# GD32F5xx register map
File version: 1.0
CPU: CM33 r0p1, little endian, MPU, FPU, 4 interrupt priority bits
Registers are 32-bit, read-write, reset 0x0 unless marked. A register's access mark holds for its fields unless they carry their own. Offsets are from the block's base; [hi:lo] are bit positions.

## TIMER9 — General-purpose-timers
Base 0x40014400
Same registers: TIMER12 0x40001C00, TIMER13 0x40002000
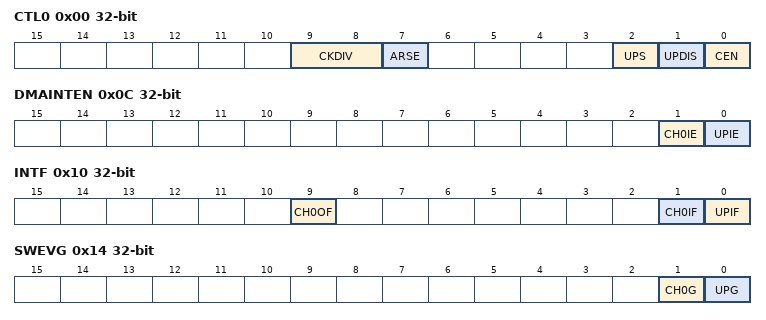
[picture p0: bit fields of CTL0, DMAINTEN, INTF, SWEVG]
0x00 CTL0 — control register 0
  [9:8] CKDIV — Clock division
  [7] ARSE — Auto-reload shadow enable
  [2] UPS — Update source
  [1] UPDIS — Update disable
  [0] CEN — Counter enable
0x04 CTL1 — control register 1
  [6:4] MMC — Master mode control
0x0C DMAINTEN — DMA/Interrupt enable register
  [1] CH0IE — Channel 0 capture/compare interrupt enable
  [0] UPIE — Update interrupt enable
0x10 INTF — interrupt flag register
  [9] CH0OF — Channel 0 over capture flag
  [1] CH0IF — Channel 0 capture/compare interrupt flag
  [0] UPIF — Update interrupt flag
0x14 SWEVG wo — event generation register
  [1] CH0G — Channel 0 capture or compare event generation
  [0] UPG — Update generation
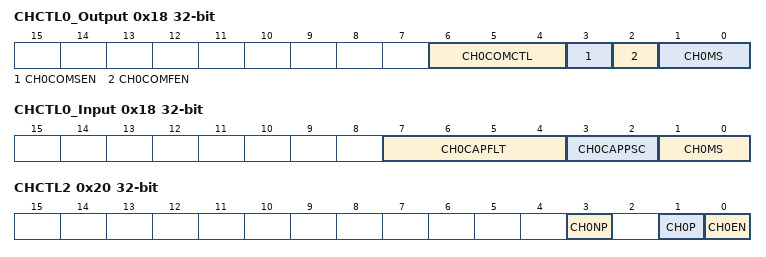
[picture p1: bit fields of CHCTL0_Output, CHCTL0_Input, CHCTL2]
0x18 CHCTL0_Output — Channel control register 0 (output mode)
  [6:4] CH0COMCTL — Channel 0 compare output control
  [3] CH0COMSEN — Channel 0 compare output shadow enable
  [2] CH0COMFEN — Channel 0 output compare fast enable
  [1:0] CH0MS — Channel 0 I/O mode selection
0x18 CHCTL0_Input (alternate view of CHCTL0_Output) — Channel control register 0 ( (input mode)
  [7:4] CH0CAPFLT — Channel 0 input capture filter control
  [3:2] CH0CAPPSC — Channel 0 input capture prescaler
  [1:0] CH0MS — Channel 0 mode selection
0x20 CHCTL2 — Channel control register 2
  [3] CH0NP — Channel 0 complementary output polarity
  [1] CH0P — Channel 0 capture/compare polarity
  [0] CH0EN — Channel 0 capture/compare function enable
0x24 CNT — Counter register
  [15:0] CNT — current counter value
0x28 PSC — Prescaler register
  [15:0] PSC — Prescaler value of the counter clock
0x2C CAR — Counter auto reload register
  [15:0] CARL — Counter auto reload value
0x34 CH0CV — Channel 0 capture/compare value register
  [15:0] CH0VAL — Capture or compare value of channel 0
0x50 IRMP — channel input remap register
  [11:10] ITI1_RMP — Internal trigger input1 remap
0xFC CFG — configuration register
  [1] CHVSEL — Write CHxVAL register selection

## TIMER10 — General level2 timer
Base 0x40014800
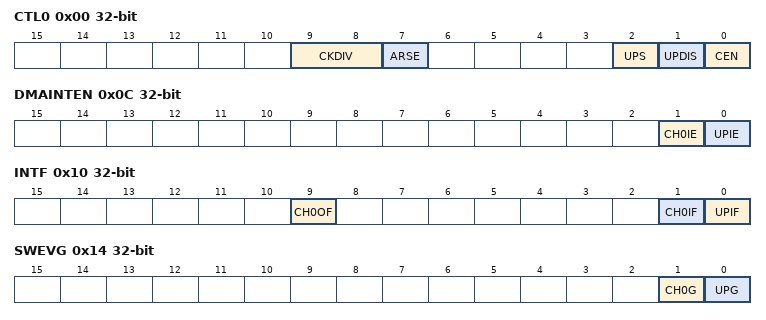
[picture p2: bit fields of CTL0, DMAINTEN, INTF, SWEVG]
0x00 CTL0 — Control register 0
  [9:8] CKDIV — Clock division
  [7] ARSE — Auto-reload shadow enable
  [2] UPS — Update source
  [1] UPDIS — Update disable.
  [0] CEN — Counter enable
0x04 CTL1 — Control register 1
  [6:4] MMC — Master mode control
0x0C DMAINTEN — Interrupt enable register
  [1] CH0IE — Channel 0 capture/compare interrupt enable
  [0] UPIE — Update interrupt enable
0x10 INTF — Interrupt flag register
  [9] CH0OF — Channel 0 over capture flag
  [1] CH0IF — Channel 0 capture/compare interrupt flag
  [0] UPIF — Update interrupt flag
0x14 SWEVG wo — Software event generation register
  [1] CH0G — Channel 0 capture or compare event generation
  [0] UPG — This bit can be set by software, and cleared by hardware automatically. When this bit is set, the counter is cleared. The prescaler counter is cleared at the same time.
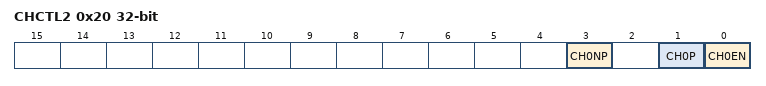
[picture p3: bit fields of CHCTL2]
0x20 CHCTL2 — Channel control register 2
  [3] CH0NP — Channel 0 complementary output polarity
  [1] CH0P — Channel 0 capture/compare polarity
  [0] CH0EN — Channel 0 capture/compare function enable
0x24 CNT — Counter register
  [15:0] CNT — This bit-filed indicates the current counter value. Writing to this bit-filed can change the value of the counter.
0x28 PSC — Prescaler register
  [15:0] PSC — Prescaler value of the counter clock
0x2C CAR reset 0xFFFF — Counter auto reload register
  [15:0] CARL — Counter auto reload value
0x34 CH0CV — Channel 0 capture/compare value register
  [15:0] CH0VAL — Capture or compare value of channel0
0x50 IRMP — Input remap register
  [11:10] ITI1_RMP — Write CHxVAL register selection
0xFC CFG — Configuration register
  [1] CHVSEL — Write CHxVAL register selection
